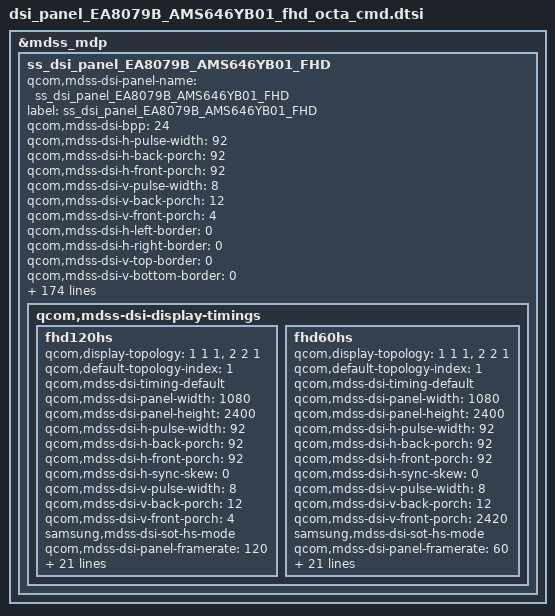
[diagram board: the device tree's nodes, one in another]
/* Copyright (c) 2020, Samsung Electronics Corporation. All rights reserved.
 *
 * This program is free software; you can redistribute it and/or modify
 * it under the terms of the GNU General Public License version 2 and
 * only version 2 as published by the Free Software Foundation.
 *
 * This program is distributed in the hope that it will be useful,
 * but WITHOUT ANY WARRANTY; without even the implied warranty of
 * MERCHANTABILITY or FITNESS FOR A PARTICULAR PURPOSE.  See the
 * GNU General Public License for more details.
 */

&mdss_mdp {
	ss_dsi_panel_EA8079B_AMS646YB01_FHD: ss_dsi_panel_EA8079B_AMS646YB01_FHD {
		qcom,mdss-dsi-panel-name = "ss_dsi_panel_EA8079B_AMS646YB01_FHD";
		label = "ss_dsi_panel_EA8079B_AMS646YB01_FHD";

		qcom,mdss-dsi-bpp = <24>;

		qcom,mdss-dsi-h-pulse-width = <92>;
		qcom,mdss-dsi-h-back-porch = <92>;
		qcom,mdss-dsi-h-front-porch = <92>;
		qcom,mdss-dsi-v-pulse-width = <8>;
		qcom,mdss-dsi-v-back-porch = <12>;
		qcom,mdss-dsi-v-front-porch = <4>;

		qcom,mdss-dsi-h-left-border = <0>;
		qcom,mdss-dsi-h-right-border = <0>;
		qcom,mdss-dsi-v-top-border = <0>;
		qcom,mdss-dsi-v-bottom-border = <0>;

		qcom,mdss-dsi-panel-phy-timings = [00 25 0A 0A 27 24 0A 0A 09 02 04 00 1F 1A];	// 1110 Mbps

		qcom,mdss-dsi-underflow-color = <0xFF>;
		qcom,mdss-dsi-border-color = <0>;

		qcom,mdss-dsi-bl-pmic-control-type = "bl_ctrl_dcs";

		qcom,mdss-dsi-bl-min-level = <1>;
		qcom,mdss-dsi-bl-max-level = <486>;
		qcom,mdss-brightness-max-level = <486>;
		qcom,mdss-brightness-default-level = <255>;
		qcom,mdss-dsi-interleave-mode = <0>;
		qcom,mdss-dsi-panel-type = "dsi_cmd_mode";

		qcom,mdss-dsi-te-check-enable;
		qcom,mdss-dsi-te-using-te-pin;
		qcom,mdss-dsi-te-pin-select = <1>;

		/*qcom,dynamic-mode-switch-enabled;*/
		/*qcom,dynamic-mode-switch-type = "dynamic-resolution-switch-immediate";*/

		qcom,mdss-dsi-te-dcs-command = <1>;
		qcom,mdss-dsi-wr-mem-start = <0x2C>;
		qcom,mdss-dsi-wr-mem-continue = <0x3C>;

		qcom,mdss-dsi-pixel-packing = "loose";

		qcom,mdss-dsi-virtual-channel-id = <0>;
		qcom,mdss-dsi-color-order = "rgb_swap_rgb";
		qcom,mdss-dsi-lane-0-state;
		qcom,mdss-dsi-lane-1-state;
		qcom,mdss-dsi-lane-2-state;
		qcom,mdss-dsi-lane-3-state;
		//qcom,mdss-dsi-lane-map = "lane_map_0123";

		qcom,mdss-dsi-t-clk-pre = <0x1F>;
		qcom,mdss-dsi-t-clk-post = <0x1A>;

		qcom,mdss-dsi-stream = <0>;
		qcom,mdss-dsi-mdp-trigger = "none";
		qcom,mdss-dsi-dma-trigger = "trigger_sw";

		qcom,mdss-pan-physical-width-dimension = <67>; /* 67.284 */
		qcom,mdss-pan-physical-height-dimension = <149>; /* 149.52 */

		qcom,mdss-dsi-reset-sequence = <0 10>, <1 15>;

		qcom,mdss-dsi-lp11-init;
		/*qcom,mdss-dsi-init-delay-us = <1000>;*/

		qcom,mdss-dsi-rx-eot-ignore;
		qcom,mdss-dsi-tx-eot-append;

		/* HDR Setting */
		qcom,mdss-dsi-panel-hdr-enabled;
		qcom,mdss-dsi-panel-hdr-color-primaries = <15635 16450 34000 16000 13250 34500 7500 3000>;
		qcom,mdss-dsi-panel-peak-brightness = <5400000>;
		qcom,mdss-dsi-panel-average-brightness = <2000000>;
		qcom,mdss-dsi-panel-blackness-level = <2000>;

		qcom,ulps-enabled;
		/* qcom,suspend-ulps-enabled; */
		qcom,esd-check-enabled;
		qcom,mdss-dsi-panel-status-check-mode ="irq_check";
		qcom,mdss-dsi-panel-status-irq-trigger1 = "falling";
		/*qcom,mdss-dsi-panel-status-read-length;*/
		/*qcom,mdss-dsi-panel-status-value;*/
		/*qcom,mdss-dsi-panel-status-irq-trigger2 = "falling";*/

		/* *************************************************************
		 * Below  parameters are samsung dependent thigs
		 * *************************************************************
		 */
		samsung,panel-vendor = "SDC";
		samsung,disp-model = "AMS646YB01";
		samsung,panel-lpm-enable;
		samsung,support_gamma_mode2;
		//samsung,elvss_interpolation_temperature = <(-15)>;
		samsung,support_factory_panel_swap;
		samsung,support_gpara;
		samsung,pll_ssc_disabled;

		/* *************************************************************
		 *  Tx
		 * *************************************************************
		 */
		samsung,level0_key_enable_tx_cmds_revA	= [29 01 00 00 00 00 03 9F A5 A5]; /* PASSWD0 */
		samsung,level0_key_disable_tx_cmds_revA	= [29 01 00 00 00 00 03 9F 5A 5A]; /* PASSWD0 */
		samsung,level1_key_enable_tx_cmds_revA	= [29 01 00 00 00 00 03 F0 5A 5A]; /* PASSWD1 */
		samsung,level1_key_disable_tx_cmds_revA	= [29 01 00 00 00 00 03 F0 A5 A5]; /* PASSWD1 */
		samsung,level2_key_enable_tx_cmds_revA	= [29 01 00 00 00 00 03 FC 5A 5A];
		samsung,level2_key_disable_tx_cmds_revA	= [29 01 00 00 00 00 03 FC A5 A5];

		/* BRIGHTNESS_MAX_PACKET = 50 */
		samsung,brightness_tx_cmds_revA = [
			39 01 00 00 00 00 01 00
			39 01 00 00 00 00 01 00
			39 01 00 00 00 00 01 00
			39 01 00 00 00 00 01 00
			39 01 00 00 00 00 01 00
			39 01 00 00 00 00 01 00
			39 01 00 00 00 00 01 00
			39 01 00 00 00 00 01 00
			39 01 00 00 00 00 01 00
			39 01 00 00 00 00 01 00
			39 01 00 00 00 00 01 00
			39 01 00 00 00 00 01 00
			39 01 00 00 00 00 01 00
			39 01 00 00 00 00 01 00
			39 01 00 00 00 00 01 00
			39 01 00 00 00 00 01 00
			39 01 00 00 00 00 01 00
			39 01 00 00 00 00 01 00
			39 01 00 00 00 00 01 00
			39 01 00 00 00 00 01 00
			39 01 00 00 00 00 01 00
			39 01 00 00 00 00 01 00
			39 01 00 00 00 00 01 00
			39 01 00 00 00 00 01 00
			39 01 00 00 00 00 01 00
			39 01 00 00 00 00 01 00
			39 01 00 00 00 00 01 00
			39 01 00 00 00 00 01 00
			39 01 00 00 00 00 01 00
			39 01 00 00 00 00 01 00
			39 01 00 00 00 00 01 00
			39 01 00 00 00 00 01 00
			39 01 00 00 00 00 01 00
			39 01 00 00 00 00 01 00
			39 01 00 00 00 00 01 00
			39 01 00 00 00 00 01 00
			39 01 00 00 00 00 01 00
			39 01 00 00 00 00 01 00
			39 01 00 00 00 00 01 00
			39 01 00 00 00 00 01 00
			39 01 00 00 00 00 01 00
			39 01 00 00 00 00 01 00
			39 01 00 00 00 00 01 00
			39 01 00 00 00 00 01 00
			39 01 00 00 00 00 01 00
			39 01 00 00 00 00 01 00
			39 01 00 00 00 00 01 00
			39 01 00 00 00 00 01 00
			39 01 00 00 00 00 01 00
			39 01 00 00 00 00 01 00
		];

		//samsung,mdnie_tx_cmds_revA = [
		//	39 01 00 00 00 00 00 00 00
		//];

		samsung,packet_size_tx_cmds_revA = [
			37 01 00 00 00 00 02 07 00
		];

		/* use poinging gpara (long write) */
		samsung,reg_read_pos_tx_cmds_revA = [
			29 00 00 00 00 00 03 B0 00 00
		];

		samsung,display_on_tx_cmds_revA = [05 01 00 00 00 00 02 29 00];
		samsung,display_off_tx_cmds_revA = [05 01 00 00 00 00 02 28 00];

		/* *************************************************************
		 *  Rx (Module Information READ)
		 * *************************************************************
		 */
		samsung,mdnie_read_rx_cmds_revA		= [06 01 00 00 00 00 01 EA 04 03]; /* White color position EA 4th ~ 7th */
		samsung,manufacture_date_rx_cmds_revA	= [06 01 00 00 00 00 01 EA 07 07]; /* manufacture data EA 8th ~ 14th*/
		samsung,octa_id_rx_cmds_revA		= [06 01 00 00 00 00 01 EA 14 0E]; /* ID (4bytes) + Cell ID(16bytes) */
		samsung,cell_id_rx_cmds_revA		= [06 01 00 00 00 00 01 EA 07 07]; /* Cell ID 16bytes EA 8th ~ 14th*/
		samsung,ddi_id_rx_cmds_revA		= [06 01 00 00 00 00 01 D1 06 60]; /* CHIP ID : read D1 96~101th */

		samsung,manufacture_id0_rx_cmds_revA	= [06 01 00 00 00 00 01 da 01 00];
		samsung,manufacture_id1_rx_cmds_revA	= [06 01 00 00 00 00 01 db 01 00];
		samsung,manufacture_id2_rx_cmds_revA	= [06 01 00 00 00 00 01 dc 01 00];

		samsung,ldi_debug0_rx_cmds_revA		= [06 01 00 00 00 00 01 0A 01 00]; /* rddpm */
		//samsung,ldi_debug1_rx_cmds_revA		= [06 01 00 00 00 00 01 0E 01 00]; /* no operation */
		samsung,ldi_debug2_rx_cmds_revA		= [06 01 00 00 00 00 01 0E 01 00]; /* errfg */
		samsung,ldi_debug3_rx_cmds_revA		= [06 01 00 00 00 00 01 0E 01 00]; /* rddsm*/
		samsung,ldi_debug4_rx_cmds_revA		= [06 01 00 00 00 00 01 05 01 00]; /* dsierr */
		//samsung,ldi_debug5_rx_cmds_revA		= [06 01 00 00 00 00 01 0F 01 00]; /* self_diag*/

		/* 255 bytes, its ddi max size is 512, and sw limit is ff = 255... */
		//samsung,ldi_debug_logbuf_rx_cmds_revA	= [06 01 00 00 00 00 01 9C FF 00];

		samsung,mtp_read_sysfs_rx_cmds_revA	= [06 01 00 00 00 00 01 00 00 00];

		samsung,mtp_write_sysfs_tx_cmds_revA	= [
			29 00 00 00 00 00 3D 00
						00 00 00 00 00 00 00 00 00 00
						00 00 00 00 00 00 00 00 00 00
						00 00 00 00 00 00 00 00 00 00
						00 00 00 00 00 00 00 00 00 00
						00 00 00 00 00 00 00 00 00 00
						00 00 00 00 00 00 00 00 00 00
		];

		/* *************************************************************
		 * ACL command list and mappings
		 * **************************************************************
		 */
		samsung,acl_on_tx_cmds_revA = [
			/* 32 frame AVG ACL ON, Start 50%, ACL 15%, 32Frame AVG */
			29 01 00 00 00 00 02 55 02	/* 8%(0x01), 15%(0x02) */
		];

		samsung,acl_off_tx_cmds_revA = [
			/* 16 Frame AVG ACL OFF, Start Point 60%, ACL 0%*/
			29 01 00 00 00 00 02 55 00	/* ACL OFF */
		];

		samsung,elvss_rx_cmds_revA = [ 06 01 00 00 00 00 01 B7 02 07];	/* read B7 8th, 9th para */

		/* *************************************************************
		 * Dynamic MIPI Clock
		 * **************************************************************
		 */
		samsung,support_dynamic_mipi_clk;
		samsung,ffc_cmds_line_position = <4>;
		samsung,ffc_tx_cmds_revA = [
			29 00 00 00 00 00 03 F0 5A 5A
			29 00 00 00 00 00 03 FC 5A 5A
			29 00 00 00 00 00 02 B0 01
			29 00 00 00 00 00 04 E4 A4 F5 BB
			29 00 00 00 00 00 0F E9 11 75 A4 F5 BB 9E 1F 46 9E 1F 46 00 32 32 /* 1110 Mbps (555) */
			29 01 00 00 00 00 03 F0 A5 A5
			29 01 00 00 00 00 03 FC A5 A5
		];

		samsung,ffc_off_tx_cmds_revA = [
			29 00 00 00 00 00 03 F0 5A 5A
			29 00 00 00 00 00 03 FC 5A 5A
			29 00 00 00 00 00 02 E9 10
			29 01 00 00 00 00 03 F0 A5 A5
			29 01 00 00 00 00 03 FC A5 A5
		];

		samsung,dyn_mipi_clk_ffc_cmds_pre_revA = [
			29 00 00 00 00 00 04 E4 A4 F5 BB /* 0 : 1110 Mbps (555) */
			29 00 00 00 00 00 04 E4 A4 F5 BB /* 1 : 1110 Mbps (555) */
			29 00 00 00 00 00 04 E4 A4 5E 19 /* 2 : 1114 Mbps (557) */
			29 00 00 00 00 00 04 E4 A2 E7 BD /* 3 : 1124 Mbps (562) */
		];

		samsung,dyn_mipi_clk_ffc_cmds_revA = [
			29 00 00 00 00 00 0F E9 11 75 A4 F5 BB 9E 1F 46 9E 1F 46 00 32 32 /* 0 : 1110 Mbps (555) */
			29 00 00 00 00 00 0F E9 11 75 A4 F5 BB 9E 1F 46 9E 1F 46 00 32 32 /* 1 : 1110 Mbps (555) */
			29 00 00 00 00 00 0F E9 11 75 A4 5E 19 9E 1F 46 9E 1F 46 00 32 32 /* 2 : 1114 Mbps (557) */
			29 00 00 00 00 00 0F E9 11 75 A2 E7 BD 9E 1F 46 9E 1F 46 00 32 32 /* 3 : 1124 Mbps (562) */
		];

		samsung,dynamic_mipi_clk_timing_table = <
			/*<bitclk><>*/
			1110000000 /* clk id 0 default */
			1110000000 /* clk id 1 A */
			1114000000 /* clk id 2 B */
			1124000000 /* clk id 3 C */
		>;

		samsung,dynamic_mipi_clk_sel_table = <
			/*<RAT><BAND><from><end><clk index>*/
                        1		1		0		0		1
                        1		2		0		0		1
                        1		3		0		0		3
                        1		4		0		0		2
                        2		11		10562		10838		1
                        2		12		9662		9677		1
                        2		12		9678		9712		2
                        2		12		9713		9747		3
                        2		12		9748		9938		1
                        2		13		1162		1178		3
                        2		13		1179		1513		1
                        2		14		1537		1738		1
                        2		15		4357		4458		1
                        2		17		2237		2271		1
                        2		17		2272		2318		2
                        2		17		2319		2341		3
                        2		17		2342		2563		1
                        2		18		2937		3088		1
                        3		91		0		599		1
                        3		92		600		654		1
                        3		92		655		724		2
                        3		92		725		794		3
                        3		92		795		1199		1
                        3		93		1200		1257		3
                        3		93		1258		1949		1
                        3		94		1950		2399		1
                        3		95		2400		2649		1
                        3		97		2750		2842		1
                        3		97		2843		2937		2
                        3		97		2938		2982		3
                        3		97		2983		3449		1
                        3		98		3450		3799		1
                        3		102		5010		5179		1
                        3		103		5180		5279		1
                        3		104		5280		5379		1
                        3		107		5730		5849		1
                        3		108		5850		5999		1
                        3		109		6000		6149		1
                        3		110		6150		6449		1
                        3		111		6450		6599		1
                        3		115		8040		8094		1
                        3		115		8095		8164		2
                        3		115		8165		8234		3
                        3		115		8235		8689		1
                        3		116		8690		9039		1
                        3		118		9210		9659		1
                        3		119		9660		9769		1
                        3		120		9770		9787		1
                        3		120		9788		9869		2
                        3		122		9920		10359		1
                        3		124		36200		36349		1
                        3		128		37750		38249		1
                        3		129		38250		38649		1
                        3		130		38650		39167		1
                        3		130		39168		39252		2
                        3		130		39253		39307		3
                        3		130		39308		39649		1
                        3		131		39650		39684		2
                        3		131		39685		39734		3
                        3		131		39735		40982		1
                        3		131		40983		41077		2
                        3		131		41078		41122		3
                        3		131		41123		41589		1
                        3		132		41590		42207		1
                        3		132		42208		42332		2
                        3		132		42333		42347		3
                        3		132		42348		43589		1
                        3		138		55240		55745		1
                        3		138		55746		55875		2
                        3		138		55876		55885		3
                        3		138		55886		56739		1
                        3		156		66436		67335		1
                        3		161		68586		68935		1
                        4		51		0		0		1
                        4		52		0		0		1
                        4		53		0		0		1
                        4		54		0		0		1
                        4		55		0		0		3
                        4		56		0		0		1
                        5		61		0		0		1
                        5		62		0		0		1
                        5		71		0		0		1
                        7		260		173800		178780		1
                        7		263		185000		191840		1
                        7		263		191841		191980		2
                        7		283		151600		160580		1
                        7		326		123400		130380		1
		>;

		/* *************************************************************
		 * candela to index mappings
		 * **************************************************************
		 */
		//samsung,gamma_mode2_candela_map_table_revA = < /* THIS TABLE USED FOR DIMMING */
		samsung,candela_map_table_revA = < /* THIS TABLE USED FOR DIMMING */
		/* <idx> <from> <till> <gm2_wrdisbv> <cd> */
                        0               0               0               5               2
                        1               1               1               9               4
                        2               2               2               12              5
                        3               3               3               16              6
                        4               4               4               19              8
                        5               5               5               23              9
                        6               6               6               26              10
                        7               7               7               30              12
                        8               8               8               33              13
                        9               9               9               37              15
                        10              10              10              40              16
                        11              11              11              44              18
                        12              12              12              47              19
                        13              13              13              51              21
                        14              14              14              54              22
                        15              15              15              58              23
                        16              16              16              61              25
                        17              17              17              65              26
                        18              18              18              68              27
                        19              19              19              72              29
                        20              20              20              75              30
                        21              21              21              79              32
                        22              22              22              82              33
                        23              23              23              86              35
                        24              24              24              89              36
                        25              25              25              93              38
                        26              26              26              96              39
                        27              27              27              100             40
                        28              28              28              103             42
                        29              29              29              107             43
                        30              30              30              110             44
                        31              31              31              114             46
                        32              32              32              117             47
                        33              33              33              121             49
                        34              34              34              125             50
                        35              35              35              128             52
                        36              36              36              132             53
                        37              37              37              135             55
                        38              38              38              139             56
                        39              39              39              142             57
                        40              40              40              146             59
                        41              41              41              149             60
                        42              42              42              153             62
                        43              43              43              156             63
                        44              44              44              160             65
                        45              45              45              163             66
                        46              46              46              167             67
                        47              47              47              170             69
                        48              48              48              174             70
                        49              49              49              177             71
                        50              50              50              181             73
                        51              51              51              184             74
                        52              52              52              188             76
                        53              53              53              191             77
                        54              54              54              195             79
                        55              55              55              198             80
                        56              56              56              202             82
                        57              57              57              205             83
                        58              58              58              209             84
                        59              59              59              212             86
                        60              60              60              216             87
                        61              61              61              219             88
                        62              62              62              223             90
                        63              63              63              226             91
                        64              64              64              230             93
                        65              65              65              234             95
                        66              66              66              237             96
                        67              67              67              241             97
                        68              68              68              244             99
                        69              69              69              248             100
                        70              70              70              251             101
                        71              71              71              255             103
                        72              72              72              258             104
                        73              73              73              262             106
                        74              74              74              265             107
                        75              75              75              269             109
                        76              76              76              272             110
                        77              77              77              276             111
                        78              78              78              279             113
                        79              79              79              283             114
                        80              80              80              286             116
                        81              81              81              290             117
                        82              82              82              293             118
                        83              83              83              297             120
                        84              84              84              300             121
                        85              85              85              304             123
                        86              86              86              307             124
                        87              87              87              311             126
                        88              88              88              314             127
                        89              89              89              318             128
                        90              90              90              321             130
                        91              91              91              325             131
                        92              92              92              328             132
                        93              93              93              332             134
                        94              94              94              335             135
                        95              95              95              339             137
                        96              96              96              342             138
                        97              97              97              346             140
                        98              98              98              350             141
                        99              99              99              353             143
                        100             100             100             357             144
                        101             101             101             360             145
                        102             102             102             364             147
                        103             103             103             367             148
                        104             104             104             371             150
                        105             105             105             374             151
                        106             106             106             378             153
                        107             107             107             381             154
                        108             108             108             385             156
                        109             109             109             388             157
                        110             110             110             392             158
                        111             111             111             395             160
                        112             112             112             399             161
                        113             113             113             402             162
                        114             114             114             406             164
                        115             115             115             409             165
                        116             116             116             413             167
                        117             117             117             416             168
                        118             118             118             420             170
                        119             119             119             423             171
                        120             120             120             427             172
                        121             121             121             430             174
                        122             122             122             434             175
                        123             123             123             437             177
                        124             124             124             441             178
                        125             125             125             444             179
                        126             126             126             448             181
                        127             127             127             451             182
                        128             128             128             453             183
                        129             129             129             457             185
                        130             130             130             462             187
                        131             131             131             466             188
                        132             132             132             471             190
                        133             133             133             475             192
                        134             134             134             480             194
                        135             135             135             484             196
                        136             136             136             489             198
                        137             137             137             493             200
                        138             138             138             498             202
                        139             139             139             502             203
                        140             140             140             507             205
                        141             141             141             511             207
                        142             142             142             516             209
                        143             143             143             520             211
                        144             144             144             525             213
                        145             145             145             529             215
                        146             146             146             534             217
                        147             147             147             538             218
                        148             148             148             543             220
                        149             149             149             547             222
                        150             150             150             552             224
                        151             151             151             556             226
                        152             152             152             561             228
                        153             153             153             565             230
                        154             154             154             570             232
                        155             155             155             574             233
                        156             156             156             579             235
                        157             157             157             583             237
                        158             158             158             588             239
                        159             159             159             592             241
                        160             160             160             597             243
                        161             161             161             601             245
                        162             162             162             606             247
                        163             163             163             610             248
                        164             164             164             615             250
                        165             165             165             619             252
                        166             166             166             624             254
                        167             167             167             628             256
                        168             168             168             633             258
                        169             169             169             637             260
                        170             170             170             641             261
                        171             171             171             646             263
                        172             172             172             650             265
                        173             173             173             655             267
                        174             174             174             659             269
                        175             175             175             664             271
                        176             176             176             668             272
                        177             177             177             673             274
                        178             178             178             677             276
                        179             179             179             682             278
                        180             180             180             686             280
                        181             181             181             691             282
                        182             182             182             695             284
                        183             183             183             700             286
                        184             184             184             704             287
                        185             185             185             709             289
                        186             186             186             713             291
                        187             187             187             718             293
                        188             188             188             722             295
                        189             189             189             727             297
                        190             190             190             731             299
                        191             191             191             736             301
                        192             192             192             740             302
                        193             193             193             745             304
                        194             194             194             749             306
                        195             195             195             754             308
                        196             196             196             758             310
                        197             197             197             763             312
                        198             198             198             767             314
                        199             199             199             772             316
                        200             200             200             776             317
                        201             201             201             781             319
                        202             202             202             785             321
                        203             203             203             790             323
                        204             204             204             794             325
                        205             205             205             799             327
                        206             206             206             803             329
                        207             207             207             808             331
                        208             208             208             812             332
                        209             209             209             817             334
                        210             210             210             821             336
                        211             211             211             826             338
                        212             212             212             830             340
                        213             213             213             834             341
                        214             214             214             839             343
                        215             215             215             843             345
                        216             216             216             848             347
                        217             217             217             852             349
                        218             218             218             857             351
                        219             219             219             861             353
                        220             220             220             866             355
                        221             221             221             870             356
                        222             222             222             875             358
                        223             223             223             879             360
                        224             224             224             884             362
                        225             225             225             888             364
                        226             226             226             893             366
                        227             227             227             897             368
                        228             228             228             902             370
                        229             229             229             906             371
                        230             230             230             911             373
                        231             231             231             915             375
                        232             232             232             920             377
                        233             233             233             924             379
                        234             234             234             929             381
                        235             235             235             933             383
                        236             236             236             938             385
                        237             237             237             942             386
                        238             238             238             947             388
                        239             239             239             951             390
                        240             240             240             956             392
                        241             241             241             960             394
                        242             242             242             965             396
                        243             243             243             969             398
                        244             244             244             974             400
                        245             245             245             978             401
                        246             246             246             983             403
                        247             247             247             987             405
                        248             248             248             992             407
                        249             249             249             996             409
                        250             250             250             1001            411
                        251             251             251             1005            413
                        252             252             252             1010            415
                        253             253             253             1014            416
                        254             254             254             1018            418
                        255             255             255             1023            420
		>;

		samsung,hbm_candela_map_table_revA = <
		/* <idx> <from> <till> <gm2_wrdisbv> <cd> <auto> */
                        0       256     256     0       445     0
                        1       257     257     3       446     0
                        2       258     258     5       448     0
                        3       259     259     8       449     0
                        4       260     260     11      451     0
                        5       261     261     13      452     0
                        6       262     262     16      454     0
                        7       263     263     19      456     0
                        8       264     264     21      457     0
                        9       265     265     24      459     0
                        10      266     266     27      460     0
                        11      267     267     29      461     0
                        12      268     268     32      463     0
                        13      269     269     35      465     0
                        14      270     270     37      466     0
                        15      271     271     40      468     0
                        16      272     272     43      470     0
                        17      273     273     45      471     0
                        18      274     274     48      473     0
                        19      275     275     51      474     0
                        20      276     276     53      475     0
                        21      277     277     56      477     0
                        22      278     278     59      479     0
                        23      279     279     61      480     0
                        24      280     280     64      482     0
                        25      281     281     67      484     0
                        26      282     282     69      485     0
                        27      283     283     72      486     0
                        28      284     284     75      488     0
                        29      285     285     77      489     0
                        30      286     286     80      491     0
                        31      287     287     83      493     0
                        32      288     288     85      494     0
                        33      289     289     88      496     0
                        34      290     290     91      497     0
                        35      291     291     93      499     0
                        36      292     292     96      500     0
                        37      293     293     99      502     0
                        38      294     294     101     503     0
                        39      295     295     104     505     0
                        40      296     296     107     507     0
                        41      297     297     109     508     0
                        42      298     298     112     510     0
                        43      299     299     115     511     0
                        44      300     300     117     512     0
                        45      301     301     120     514     0
                        46      302     302     123     516     0
                        47      303     303     125     517     0
                        48      304     304     128     519     0
                        49      305     305     131     521     0
                        50      306     306     133     522     0
                        51      307     307     136     524     0
                        52      308     308     139     525     0
                        53      309     309     141     526     0
                        54      310     310     144     528     0
                        55      311     311     147     530     0
                        56      312     312     149     531     0
                        57      313     313     152     533     0
                        58      314     314     155     535     0
                        59      315     315     157     536     0
                        60      316     316     160     537     0
                        61      317     317     163     539     0
                        62      318     318     165     540     0
                        63      319     319     168     542     0
                        64      320     320     171     544     0
                        65      321     321     173     545     0
                        66      322     322     176     547     0
                        67      323     323     179     548     0
                        68      324     324     181     550     0
                        69      325     325     184     551     0
                        70      326     326     187     553     0
                        71      327     327     189     554     0
                        72      328     328     192     556     0
                        73      329     329     195     558     0
                        74      330     330     197     559     0
                        75      331     331     200     561     0
                        76      332     332     203     562     0
                        77      333     333     205     564     0
                        78      334     334     208     565     0
                        79      335     335     211     567     0
                        80      336     336     213     568     0
                        81      337     337     216     570     0
                        82      338     338     219     572     0
                        83      339     339     221     573     0
                        84      340     340     224     575     0
                        85      341     341     227     576     0
                        86      342     342     229     577     0
                        87      343     343     232     579     0
                        88      344     344     235     581     0
                        89      345     345     237     582     0
                        90      346     346     240     584     0
                        91      347     347     243     586     0
                        92      348     348     245     587     0
                        93      349     349     248     588     0
                        94      350     350     251     590     0
                        95      351     351     253     591     0
                        96      352     352     256     593     0
                        97      353     353     259     595     0
                        98      354     354     261     596     0
                        99      355     355     264     598     0
                        100     356     356     267     599     0
                        101     357     357     269     601     0
                        102     358     358     272     602     0
                        103     359     359     275     604     0
                        104     360     360     277     605     0
                        105     361     361     280     607     0
                        106     362     362     283     609     0
                        107     363     363     285     610     0
                        108     364     364     288     612     0
                        109     365     365     291     613     0
                        110     366     366     293     615     0
                        111     367     367     296     616     0
                        112     368     368     298     617     0
                        113     369     369     301     619     0
                        114     370     370     304     621     0
                        115     371     371     306     622     0
                        116     372     372     309     624     0
                        117     373     373     312     626     0
                        118     374     374     314     627     0
                        119     375     375     317     628     0
                        120     376     376     320     630     0
                        121     377     377     322     631     0
                        122     378     378     325     633     0
                        123     379     379     328     635     0
                        124     380     380     330     636     0
                        125     381     381     333     638     0
                        126     382     382     336     639     0
                        127     383     383     338     641     0
                        128     384     384     341     642     0
                        129     385     385     344     644     0
                        130     386     386     346     645     0
                        131     387     387     349     647     0
                        132     388     388     352     649     0
                        133     389     389     354     650     0
                        134     390     390     357     652     0
                        135     391     391     360     653     0
                        136     392     392     362     655     0
                        137     393     393     365     656     0
                        138     394     394     368     658     0
                        139     395     395     370     659     0
                        140     396     396     373     661     0
                        141     397     397     376     663     0
                        142     398     398     378     664     0
                        143     399     399     381     666     0
                        144     400     400     384     667     0
                        145     401     401     386     668     0
                        146     402     402     389     670     0
                        147     403     403     392     672     0
                        148     404     404     394     673     0
                        149     405     405     397     675     0
                        150     406     406     400     677     0
                        151     407     407     402     678     0
                        152     408     408     405     679     0
                        153     409     409     408     681     0
                        154     410     410     410     682     0
                        155     411     411     413     684     0
                        156     412     412     416     686     0
                        157     413     413     418     687     0
                        158     414     414     421     689     0
                        159     415     415     424     690     0
                        160     416     416     426     692     0
                        161     417     417     429     693     0
                        162     418     418     432     695     0
                        163     419     419     434     696     0
                        164     420     420     437     698     0
                        165     421     421     440     700     0
                        166     422     422     442     701     0
                        167     423     423     445     703     0
                        168     424     424     448     704     0
                        169     425     425     450     706     0
                        170     426     426     453     707     0
                        171     427     427     456     709     0
                        172     428     428     458     710     0
                        173     429     429     461     712     0
                        174     430     430     464     714     0
                        175     431     431     466     715     0
                        176     432     432     469     717     0
                        177     433     433     472     718     0
                        178     434     434     474     719     0
                        179     435     435     477     721     0
                        180     436     436     480     723     0
                        181     437     437     482     724     0
                        182     438     438     485     726     0
                        183     439     439     488     728     0
                        184     440     440     490     729     0
                        185     441     441     493     730     0
                        186     442     442     496     732     0
                        187     443     443     498     733     0
                        188     444     444     501     735     0
                        189     445     445     504     737     0
                        190     446     446     506     738     0
                        191     447     447     509     740     0
                        192     448     448     512     741     0
                        193     449     449     514     743     0
                        194     450     450     517     744     0
                        195     451     451     520     746     0
                        196     452     452     522     747     0
                        197     453     453     525     749     0
                        198     454     454     528     751     0
                        199     455     455     530     752     0
                        200     456     456     533     754     0
                        201     457     457     536     755     0
                        202     458     458     538     757     0
                        203     459     459     541     758     0
                        204     460     460     544     760     0
                        205     461     461     546     761     0
                        206     462     462     549     763     0
                        207     463     463     552     765     0
                        208     464     464     554     766     0
                        209     465     465     557     768     0
                        210     466     466     560     769     0
                        211     467     467     562     770     0
                        212     468     468     565     772     0
                        213     469     469     568     774     0
                        214     470     470     570     775     0
                        215     471     471     573     777     0
                        216     472     472     576     779     0
                        217     473     473     578     780     0
                        218     474     474     581     781     0
                        219     475     475     584     783     0
                        220     476     476     586     784     0
                        221     477     477     589     786     0
                        222     478     478     592     788     0
                        223     479     479     594     789     0
                        224     480     480     597     791     0
                        225     481     481     600     792     0
                        226     482     482     602     794     0
                        227     483     483     605     795     0
                        228     484     484     608     797     0
                        229     485     485     610     798     0
                        230     486     486     613     800     0
		>;

		samsung,aod_candela_map_table_revA = <
		/* <idx> <from> <till> <gm2_wrdisbv> <cd> */
			0	0	5	0	2
			1	6	19	0	10
			2	20	40	0	30
			3	41	255	0	60
		>;

		samsung,gamma_mode2_normal_tx_cmds_revA=[
			39 00 00 00 00 00 02 60 10
			39 00 00 00 00 00 02 53 20
			39 00 00 00 00 00 07 B7 01 5C CB 0D C0 16
			39 01 00 00 00 00 03 51 03 FF
			39 00 00 00 00 00 02 B0 2D
			39 00 00 00 00 00 02 B7 19
		];

		samsung,gamma_mode2_hbm_tx_cmds_revA=[
			39 00 00 00 00 00 02 60 10
			39 00 00 00 00 00 02 53 20
			39 00 00 00 00 00 07 B7 01 5C CB 0D C0 16
			39 01 00 00 00 00 03 51 03 FF
			39 00 00 00 00 00 02 B0 2D
			39 00 00 00 00 00 02 B7 19
		];

		//samsung,gamma_mode2_hbm_60hz_tx_cmds_revA=[
		//];
		/* *************************************************************
		 *  HMT
		 * **************************************************************
		 */
		samsung,hmt_enabled;
		samsung,hmt_candela_map_table_revA = <
		/*<idx>	  <from>  <till> <scaled_level> */
			0		0		0		268
			1		1		1		271
			2		2		2		274
			3		3		3		277
			4		4		4		280
			5		5		5		283
			6		6		6		286
			7		7		7		289
			8		8		8		292
			9		9		9		295
			10		10		10		298
			11		11		11		301
			12		12		12		304
			13		13		13		306
			14		14		14		309
			15		15		15		312
			16		16		16		315
			17		17		17		318
			18		18		18		321
			19		19		19		324
			20		20		20		327
			21		21		21		330
			22		22		22		333
			23		23		23		336
			24		24		24		339
			25		25		25		342
			26		26		26		345
			27		27		27		348
			28		28		28		351
			29		29		29		354
			30		30		30		357
			31		31		31		360
			32		32		32		363
			33		33		33		366
			34		34		34		369
			35		35		35		372
			36		36		36		375
			37		37		37		378
			38		38		38		380
			39		39		39		383
			40		40		40		386
			41		41		41		389
			42		42		42		392
			43		43		43		395
			44		44		44		398
			45		45		45		401
			46		46		46		404
			47		47		47		407
			48		48		48		410
			49		49		49		413
			50		50		50		416
			51		51		51		419
			52		52		52		422
			53		53		53		425
			54		54		54		428
			55		55		55		431
			56		56		56		434
			57		57		57		437
			58		58		58		440
			59		59		59		443
			60		60		60		446
			61		61		61		449
			62		62		62		452
			63		63		63		455
			64		64		64		457
			65		65		65		460
			66		66		66		463
			67		67		67		466
			68		68		68		469
			69		69		69		472
			70		70		70		475
			71		71		71		478
			72		72		72		481
			73		73		73		484
			74		74		74		487
			75		75		75		490
			76		76		76		493
			77		77		77		496
			78		78		78		499
			79		79		79		502
			80		80		80		505
			81		81		81		508
			82		82		82		511
			83		83		83		514
			84		84		84		517
			85		85		85		520
			86		86		86		523
			87		87		87		526
			88		88		88		529
			89		89		89		531
			90		90		90		534
			91		91		91		537
			92		92		92		540
			93		93		93		543
			94		94		94		546
			95		95		95		549
			96		96		96		552
			97		97		97		555
			98		98		98		558
			99		99		99		561
			100		100		100		564
			101		101		101		567
			102		102		102		570
			103		103		103		573
			104		104		104		576
			105		105		105		579
			106		106		106		582
			107		107		107		585
			108		108		108		588
			109		109		109		591
			110		110		110		594
			111		111		111		597
			112		112		112		600
			113		113		113		603
			114		114		114		606
			115		115		115		608
			116		116		116		611
			117		117		117		614
			118		118		118		617
			119		119		119		620
			120		120		120		623
			121		121		121		626
			122		122		122		629
			123		123		123		632
			124		124		124		635
			125		125		125		638
			126		126		126		641
			127		127		127		644
			128		128		128		647
			129		129		129		650
			130		130		130		653
			131		131		131		656
			132		132		132		659
			133		133		133		662
			134		134		134		665
			135		135		135		668
			136		136		136		671
			137		137		137		674
			138		138		138		677
			139		139		139		680
			140		140		140		682
			141		141		141		685
			142		142		142		688
			143		143		143		691
			144		144		144		694
			145		145		145		697
			146		146		146		700
			147		147		147		703
			148		148		148		706
			149		149		149		709
			150		150		150		712
			151		151		151		715
			152		152		152		718
			153		153		153		721
			154		154		154		724
			155		155		155		727
			156		156		156		730
			157		157		157		733
			158		158		158		736
			159		159		159		739
			160		160		160		742
			161		161		161		745
			162		162		162		748
			163		163		163		751
			164		164		164		754
			165		165		165		757
			166		166		166		759
			167		167		167		762
			168		168		168		765
			169		169		169		768
			170		170		170		771
			171		171		171		774
			172		172		172		777
			173		173		173		780
			174		174		174		783
			175		175		175		786
			176		176		176		789
			177		177		177		792
			178		178		178		795
			179		179		179		798
			180		180		180		801
			181		181		181		804
			182		182		182		807
			183		183		183		810
			184		184		184		813
			185		185		185		816
			186		186		186		819
			187		187		187		822
			188		188		188		825
			189		189		189		828
			190		190		190		831
			191		191		191		833
			192		192		192		836
			193		193		193		839
			194		194		194		842
			195		195		195		845
			196		196		196		848
			197		197		197		851
			198		198		198		854
			199		199		199		857
			200		200		200		860
			201		201		201		863
			202		202		202		866
			203		203		203		869
			204		204		204		872
			205		205		205		875
			206		206		206		878
			207		207		207		881
			208		208		208		884
			209		209		209		887
			210		210		210		890
			211		211		211		893
			212		212		212		896
			213		213		213		899
			214		214		214		902
			215		215		215		905
			216		216		216		908
			217		217		217		910
			218		218		218		913
			219		219		219		916
			220		220		220		919
			221		221		221		922
			222		222		222		925
			223		223		223		928
			224		224		224		931
			225		225		225		934
			226		226		226		937
			227		227		227		940
			228		228		228		943
			229		229		229		946
			230		230		230		949
			231		231		231		952
			232		232		232		955
			233		233		233		958
			234		234		234		961
			235		235		235		964
			236		236		236		967
			237		237		237		970
			238		238		238		973
			239		239		239		976
			240		240		240		979
			241		241		241		982
			242		242		242		984
			243		243		243		987
			244		244		244		990
			245		245		245		993
			246		246		246		996
			247		247		247		999
			248		248		248		1002
			249		249		249		1005
			250		250		250		1008
			251		251		251		1011
			252		252		252		1014
			253		253		253		1017
			254		254		254		1020
			255		255		255		1023
		>;

		samsung,hmt_enable_tx_cmds_revA = [
			29 00 00 00 00 00 03 F0 5A 5A				/* Test Key Enable */
			29 00 00 00 00 00 03 B0 E0 B7				/* Global Para */
			29 00 00 00 00 00 03 B7 07 9A				/* AOR 80% */
			29 00 00 00 00 00 03 CB 00 00 42 03 00 0E	/* LTPS Setting */
			29 00 00 00 00 00 02 F7 03					/* LTPS Update */
			29 01 00 00 00 00 03 F0 A5 A5				/* Test Key Disable */
		];

		samsung,hmt_disable_tx_cmds_revA = [
			29 00 00 00 00 00 03 F0 5A 5A				/* Test Key Enable */
			29 00 00 00 00 00 03 B0 E0 B7				/* Global Para */
			29 00 00 00 00 00 03 B7 00 18				/* AOR 0% */
			29 00 00 00 00 00 03 CB 00 00 42 0B 00 06	/* LTPS Setting */
			29 00 00 00 00 00 02 F7 03					/* LTPS Update */
			29 01 00 00 00 00 03 F0 A5 A5				/* Test Key Disable */
		];

		samsung,gamma_mode2_hmt_tx_cmds_revA=[
			29 01 00 00 00 00 03 51 03 FF
		];

		/*
		 * ************************************************************************************************************************
		 *  FD Settings
		 * ************************************************************************************************************************
		 */

		samsung,fd_on_tx_cmds_revA = [
			29 00 00 00 00 00 03 F0 5A 5A
			29 00 00 00 00 00 02 B0 0A
			29 00 00 00 00 00 02 D5 01
			29 01 00 00 00 00 03 F0 A5 A5
		];

		samsung,fd_off_tx_cmds_revA = [
			29 00 00 00 00 00 03 F0 5A 5A
			29 00 00 00 00 00 02 B0 0A
			29 00 00 00 00 00 02 D5 02
			29 01 00 00 00 00 03 F0 A5 A5
		];

		/* *************************************************************
		 *   APLPM
		 * *************************************************************
		 */

		samsung,lpm_on_tx_cmds_revA = [ // TX_LPM_ON
			/* Image write for HLPM/ALPM Mode */
			29 00 00 00 00 00 03 F0 5A 5A
			29 00 00 00 00 00 02 E3 00	/* HLPM Select : HLPM(00)/ALPM(01) */
			29 00 00 00 00 00 02 60 10
			29 00 00 00 00 00 02 B0 0B	/* Global Para */
			29 00 00 00 00 00 03 BB 00 14	/* HLPM AOR Setting */
			29 00 00 00 01 00 02 53 23		/* HLPM On Setting */
			29 01 00 00 11 00 03 F0 A5 A5
		];

		samsung,lpm_off_tx_cmds_revA = [
			/* Image write for Normal Mode */
			29 00 00 00 00 00 03 F0 5A 5A
			29 00 00 00 00 00 07 B7 01 5C CB 0D C0 16	/* Elvss Return */
			29 00 00 00 01 00 02 53 20		/* ALPM/HLPM off */
			29 01 00 00 00 00 03 F0 A5 A5
		];

		/* ALPM/HLPM 2nit or 60nit On Commands */
		samsung,lpm_2nit_tx_cmds_revA  = [29 01 00 00 00 00 02 53 23];
		samsung,lpm_10nit_tx_cmds_revA = [29 01 00 00 00 00 02 53 23];
		samsung,lpm_30nit_tx_cmds_revA = [29 01 00 00 00 00 02 53 23];
		samsung,lpm_60nit_tx_cmds_revA = [29 01 00 00 00 00 02 53 23];

		/* HLPM / ALPM Control Commands */
		samsung,lpm_ctrl_hlpm_2nit_tx_cmds_revA  = [29 01 00 00 00 00 03 BB 09 24];
		samsung,lpm_ctrl_hlpm_10nit_tx_cmds_revA = [29 01 00 00 00 00 03 BB 08 00];
		samsung,lpm_ctrl_hlpm_30nit_tx_cmds_revA = [29 01 00 00 00 00 03 BB 04 F0];
		samsung,lpm_ctrl_hlpm_60nit_tx_cmds_revA = [29 01 00 00 00 00 03 BB 00 14];

		/* HLPM / ALPM brightness Commands: default HLPM 2nit */
		samsung,lpm_brightnes_tx_cmds_revA = [
			29 00 00 00 00 00 03 F0 5A 5A	/* TEST KEY Enable */
			29 00 00 00 00 00 02 B0 0B	/* Global Para */
			29 00 00 00 00 00 03 BB 09 24	/* HLPM AOR SETTING */
			29 00 00 00 01 00 02 53 23		/* HLPM On Setting */
			29 01 00 00 00 00 03 F0 A5 A5	/* TEST KEY Disable */
		];

		/* *************************************************************
		 *  VRR
		 * **************************************************************
		 */
		samsung,vrr_tx_cmds_revA = [
			29 00 00 00 00 00 03 F0 5A 5A
			29 00 00 00 00 00 02 60 00
			29 00 00 00 00 00 02 B0 0B
			29 00 00 00 00 00 03 D8 A9 70
			29 00 00 00 00 00 02 B0 D4
			29 00 00 00 00 00 19 BA
				12 E0 09 70 09 70 09 70
				09 70 09 70 09 70 09 70
				09 70 09 70 09 34 01 80
			29 00 00 00 00 00 08 BB 70 09 34 01 80 20 80
			29 00 00 00 00 00 02 F7 03
			29 01 00 00 00 00 03 F0 A5 A5
		];

		samsung,support_vrr_based_bl; /* VRR Variable Refresh Rate */

		/*
		* ************************************************************************************************************************
		*  DMS (Dynamic Mode Switch)
		* ************************************************************************************************************************
		*/

		qcom,mdss-dsi-display-timings {
			fhd120hs {
				qcom,display-topology = <1 1 1>, <2 2 1>; // lm, enc, intf
				qcom,default-topology-index = <1>;
				qcom,mdss-dsi-timing-default;
				qcom,mdss-dsi-panel-width = <1080>;
				qcom,mdss-dsi-panel-height = <2400>;

				qcom,mdss-dsi-h-pulse-width = <92>;
				qcom,mdss-dsi-h-back-porch = <92>;
				qcom,mdss-dsi-h-front-porch = <92>;
				qcom,mdss-dsi-h-sync-skew = <0>;

				qcom,mdss-dsi-v-pulse-width = <8>;
				qcom,mdss-dsi-v-back-porch = <12>;
				qcom,mdss-dsi-v-front-porch = <4>;

				samsung,mdss-dsi-sot-hs-mode; // HS Setting
				qcom,mdss-dsi-panel-framerate = <120>;
				qcom,mdss-mdp-transfer-time-us = <7533>; /* transfer time: 48Hz: 20032, 60Hz: 15866, 96Hz: 9616, 120Hz: 7533 */

				qcom,mdss-dsi-panel-clockrate = <1110000000>; /* 1110 Mbps*/
				qcom,mdss-dsi-panel-phy-timings = [00 25 0A 0A 27 24 0A 0A 09 02 04 00 1F 1A];	// 1110 Mbps

				/*qcom,mdss-dsi-timing-switch-command; use samsung,panel_multires_XXX instead*/
				/*qcom,mdss-dsi-timing-switch-command-state;*/
				//qcom,mdss-dsi-timing-switch-command = [ /* Freq Setting: 120Hz */
				//	39 01 00 00 00 00 02 60 10
				//];

				qcom,mdss-dsi-t-clk-pre = <0x1F>;
				qcom,mdss-dsi-t-clk-post = <0x1A>;

				qcom,mdss-dsi-on-command = [
					/* Sleep out, wait 10ms(0x0A) */
					05 01 00 00 0A 00 02 11 00

					/* TE Vsync On */
					29 00 00 00 00 00 03 F0 5A 5A
					29 00 00 00 00 00 02 35 00
					29 01 00 00 00 00 03 F0 A5 A5

					/* PAGE Address Setting */
					29 00 00 00 00 00 05 2A 00 00 04 37
					29 01 00 00 00 00 05 2B 00 00 09 5F

					/* ERR_FG Setting */
					29 00 00 00 00 00 03 F0 5A 5A
					29 00 00 00 00 00 0F EC 00 00 00 C0 42 00 00 00 20 00 00 00 00 19
					29 00 00 00 00 00 03 F0 A5 A5

					/* Vsync Setting */
					29 00 00 00 00 00 03 F0 5A 5A
					29 00 00 00 00 00 02 B0 01
					29 00 00 00 00 00 02 E6 01
					29 01 00 00 00 00 03 F0 A5 A5

					/* PCD Setting */
					29 00 00 00 00 00 03 F0 5A 5A
					29 00 00 00 00 00 03 E8 55 12 // Default Low(55) / Disable SW Reset (12)
					29 01 00 00 00 00 03 F0 A5 A5

					/* ACL Setting Value */
					29 00 00 00 00 00 03 F0 5A 5A
					29 00 00 00 00 00 02 B0 CA
					29 00 00 00 00 00 02 BB 0B
					29 00 00 00 00 00 02 B0 CF
					29 00 00 00 00 00 03 BB 41 FF
					29 00 00 00 00 00 02 B0 D9
					29 00 00 00 00 00 02 BB 20
					29 01 00 00 00 00 03 F0 A5 A5

					/* DSC Setting */
					29 01 00 00 00 00 03 F0 5A 5A
					07 01 00 00 00 00 01 01               /* Compression Enable */
					0A 01 00 00 00 00 80                  /* PPS setting */
						11 00 00 89 30 80 09
						60 04 38 00 28 02 1C
						02 1C 02 00 02 0E 00
						20 03 DD 00 07 00 0C
						02 77 02 8B 18 00 10
						F0 03 0C 20 00 06 0B
						0B 33 0E 1C 2A 38 46
						54 62 69 70 77 79 7B
						7D 7E 01 02 01 00 09
						40 09 BE 19 FC 19 FA
						19 F8 1A 38 1A 78 1A
						B6 2A F6 2B 34 2B 74
						3B 74 6B F4 00 00 00
						00 00 00 00 00 00 00
						00 00 00 00 00 00 00
						00 00 00 00 00 00 00
						00 00 00 00 00 00 00
						00 00 00 00 00 00 00
						00 00
					29 01 00 00 00 00 03 F0 A5 A5

					/* TE Setting */
					29 00 00 00 00 00 03 F0 5A 5A
					29 00 00 00 00 00 02 B0 04
					29 00 00 00 00 00 04 DF 95 80 0C
					29 01 00 00 00 00 03 F0 A5 A5

					/* Smooth Dimming Setting */
					29 00 00 00 00 00 03 F0 5A 5A
					29 00 00 00 00 00 02 B0 06
					29 00 00 00 00 00 02 B7 08
					29 01 00 00 00 00 03 F0 A5 A5

					/* Brightness */
					29 00 00 00 00 00 03 F0 5A 5A
					29 00 00 00 00 00 02 60 10		/* 0x10 : 120 Hz */
					29 00 00 00 00 00 02 53 20		/* Dimming Speed */
					29 00 00 00 00 00 07 B7 01 5C CB 0D C0 16	/* ELVSS */
					29 01 00 00 00 00 03 51 03 FF		/* 420 nit */
					29 01 00 00 6E 00 03 F0 A5 A5
					/* Wait 110ms(0x6E) */
				];

				qcom,mdss-dsi-off-command=[
					05 01 00 00 14 00 02 28 00	/* wait 20ms(0x14) */
					05 01 00 00 78 00 02 10 00
				];

				qcom,mdss-dsi-on-command-state = "dsi_hs_mode"; /* Magna DSC command only works in HS. */
				qcom,mdss-dsi-off-command-state = "dsi_hs_mode";

				qcom,compression-mode = "dsc";
				qcom,lm-split = <540 540>;
				qcom,mdss-dsc-encoders = <2>;
				qcom,mdss-dsc-slice-height = <40>;
				qcom,mdss-dsc-slice-width = <540>;
				qcom,mdss-dsc-slice-per-pkt = <1>;
				qcom,mdss-dsc-bit-per-component = <8>;
				qcom,mdss-dsc-bit-per-pixel = <8>;
				qcom,mdss-dsc-block-prediction-enable;
			};

			fhd60hs {
				qcom,display-topology = <1 1 1>, <2 2 1>;
				qcom,default-topology-index = <1>;
				qcom,mdss-dsi-timing-default;
				qcom,mdss-dsi-panel-width = <1080>;
				qcom,mdss-dsi-panel-height = <2400>;

				qcom,mdss-dsi-h-pulse-width = <92>;
				qcom,mdss-dsi-h-back-porch = <92>;
				qcom,mdss-dsi-h-front-porch = <92>;
				qcom,mdss-dsi-h-sync-skew = <0>;

				qcom,mdss-dsi-v-pulse-width = <8>;
				qcom,mdss-dsi-v-back-porch = <12>;
				qcom,mdss-dsi-v-front-porch = <2420>;

				samsung,mdss-dsi-sot-hs-mode; // HS Setting
				qcom,mdss-dsi-panel-framerate = <60>;
				qcom,mdss-mdp-transfer-time-us = <7533>; /* transfer time: 48Hz: 20032, 60Hz: 15866, 96Hz: 9616, 120Hz: 7533 */
				qcom,mdss-dsi-panel-clockrate = <1110000000>; /* 1110 Mbps*/
				qcom,mdss-dsi-panel-phy-timings = [00 25 0A 0A 27 24 0A 0A 09 02 04 00 1F 1A];	// 1110 Mbps

				/*qcom,mdss-dsi-timing-switch-command; use samsung,panel_multires_XXX instead*/
				/*qcom,mdss-dsi-timing-switch-command-state;*/
				//qcom,mdss-dsi-timing-switch-command = [ /* Freq Setting: 60*/
				//	39 01 00 00 00 00 02 60 00
				//];

				qcom,mdss-dsi-t-clk-pre = <0x1F>;
				qcom,mdss-dsi-t-clk-post = <0x1A>;

				qcom,mdss-dsi-on-command = [
					/* Sleep out, wait 10ms(0x0A) */
					05 01 00 00 0A 00 02 11 00

					/* TE Vsync On */
					29 00 00 00 00 00 03 F0 5A 5A
					29 00 00 00 00 00 02 35 00
					29 01 00 00 00 00 03 F0 A5 A5

					/* PAGE Address Setting */
					29 00 00 00 00 00 05 2A 00 00 04 37
					29 01 00 00 00 00 05 2B 00 00 09 5F

					/* ERR_FG Setting */
					29 00 00 00 00 00 03 F0 5A 5A
					29 00 00 00 00 00 0F EC 00 00 00 C0 42 00 00 00 20 00 00 00 00 19
					29 00 00 00 00 00 03 F0 A5 A5

					/* Vsync Setting */
					29 00 00 00 00 00 03 F0 5A 5A
					29 00 00 00 00 00 02 B0 01
					29 00 00 00 00 00 02 E6 01
					29 01 00 00 00 00 03 F0 A5 A5

					/* PCD Setting */
					29 00 00 00 00 00 03 F0 5A 5A
					29 00 00 00 00 00 03 E8 55 12 // Default Low(55) / Disable SW Reset (12)
					29 01 00 00 00 00 03 F0 A5 A5

					/* ACL Setting Value */
					29 00 00 00 00 00 03 F0 5A 5A
					29 00 00 00 00 00 02 B0 CA
					29 00 00 00 00 00 02 BB 0B
					29 00 00 00 00 00 02 B0 CF
					29 00 00 00 00 00 03 BB 41 FF
					29 00 00 00 00 00 02 B0 D9
					29 00 00 00 00 00 02 BB 20
					29 01 00 00 00 00 03 F0 A5 A5

					/* DSC Setting */
					29 01 00 00 00 00 03 F0 5A 5A
					07 01 00 00 00 00 01 01               /* Compression Enable */
					0A 01 00 00 00 00 80                  /* PPS setting */
						11 00 00 89 30 80 09
						60 04 38 00 28 02 1C
						02 1C 02 00 02 0E 00
						20 03 DD 00 07 00 0C
						02 77 02 8B 18 00 10
						F0 03 0C 20 00 06 0B
						0B 33 0E 1C 2A 38 46
						54 62 69 70 77 79 7B
						7D 7E 01 02 01 00 09
						40 09 BE 19 FC 19 FA
						19 F8 1A 38 1A 78 1A
						B6 2A F6 2B 34 2B 74
						3B 74 6B F4 00 00 00
						00 00 00 00 00 00 00
						00 00 00 00 00 00 00
						00 00 00 00 00 00 00
						00 00 00 00 00 00 00
						00 00 00 00 00 00 00
						00 00
					29 01 00 00 00 00 03 F0 A5 A5

					/* A-sync Setting */
					29 01 00 00 00 00 03 F0 5A 5A
					29 00 00 00 00 00 02 60 00		/* 0x00 : 96/60/48 Hz */
					29 00 00 00 00 00 02 B0 0B
					29 00 00 00 00 00 03 D8 A9 70
					29 00 00 00 00 00 02 B0 D4
					29 00 00 00 00 00 19 BA
						12 E0 09 70 09 70 09 70
						09 70 09 70 09 70 09 70
						09 70 09 70 09 34 01 80
					29 00 00 00 00 00 08 BB 70 09 34 01 80 20 80
					29 00 00 00 00 00 02 F7 03
					29 01 00 00 00 00 03 F0 A5 A5

					/* TE Setting */
					29 00 00 00 00 00 03 F0 5A 5A
					29 00 00 00 00 00 02 B0 04
					29 00 00 00 00 00 04 DF 95 80 0C
					29 01 00 00 00 00 03 F0 A5 A5

					/* Smooth Dimming Setting */
					29 00 00 00 00 00 03 F0 5A 5A
					29 00 00 00 00 00 02 B0 06
					29 00 00 00 00 00 02 B7 08
					29 01 00 00 00 00 03 F0 A5 A5

					/* Brightness */
					29 00 00 00 00 00 03 F0 5A 5A
					29 00 00 00 00 00 02 60 00		/* 0x00 : 60 Hz */
					29 00 00 00 00 00 02 53 20		/* Dimming Speed */
					29 00 00 00 00 00 07 B7 01 5C CB 0D C0 16	/* ELVSS */
					29 01 00 00 00 00 03 51 03 FF	/* 420 nit */
					29 01 00 00 6E 00 03 F0 A5 A5
					/* Wait 110ms(0x6E) */
				];

				qcom,mdss-dsi-off-command=[
					05 01 00 00 14 00 02 28 00	/* wait 20ms(0x14) */
					05 01 00 00 78 00 02 10 00
				];

				qcom,mdss-dsi-on-command-state = "dsi_hs_mode";  /* Magna DSC command only works in HS. */
				qcom,mdss-dsi-off-command-state = "dsi_hs_mode";

				qcom,compression-mode = "dsc";
				qcom,lm-split = <540 540>;
				qcom,mdss-dsc-encoders = <2>;
				qcom,mdss-dsc-slice-height = <40>;
				qcom,mdss-dsc-slice-width = <540>;
				qcom,mdss-dsc-slice-per-pkt = <1>;
				qcom,mdss-dsc-bit-per-component = <8>;
				qcom,mdss-dsc-bit-per-pixel = <8>;
				qcom,mdss-dsc-block-prediction-enable;
			};
		};
	};
};
